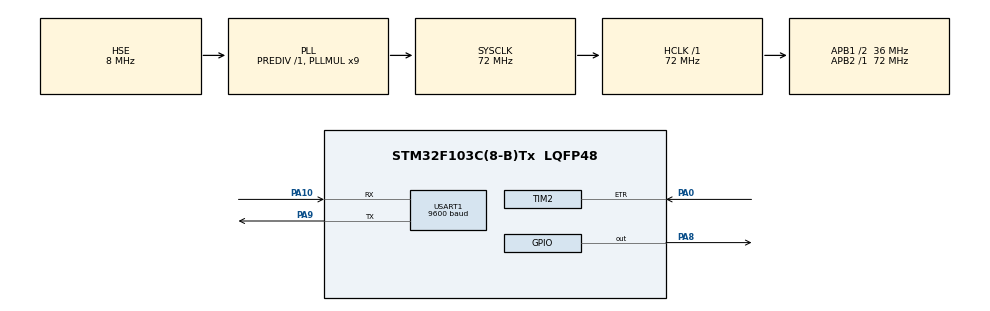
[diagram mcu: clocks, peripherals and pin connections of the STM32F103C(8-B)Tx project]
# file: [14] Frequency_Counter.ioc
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Mcu.Family=STM32F1
RCC.PLLSourceVirtual=RCC_PLLSOURCE_HSE
PD1-OSC_OUT.Mode=HSE-External-Oscillator
PA10.Mode=Asynchronous
TIM3.AutoReloadPreload=TIM_AUTORELOAD_PRELOAD_ENABLE
USART1.BaudRate=9600
PD0-OSC_IN.Signal=RCC_OSC_IN
RCC.APB1CLKDivider=RCC_HCLK_DIV2
VP_SYS_VS_ND.Mode=No_Debug
RCC.SYSCLKSource=RCC_SYSCLKSOURCE_PLLCLK
ProjectManager.StackSize=0x400
PA0-WKUP.Signal=S_TIM2_CH1_ETR
PD1-OSC_OUT.Signal=RCC_OSC_OUT
PA9.Mode=Asynchronous
ProjectManager.TargetToolchain=STM32CubeIDE
RCC.HCLKFreq_Value=72000000
RCC.APB2TimFreq_Value=72000000
PA9.Signal=USART1_TX
RCC.USBFreq_Value=72000000
RCC.AHBFreq_Value=72000000
PD0-OSC_IN.Mode=HSE-External-Oscillator
board=custom
RCC.PLLMUL=RCC_PLL_MUL9
NVIC.TIM3_IRQn=true\:0\:0\:false\:false\:true\:true\:true
RCC.APB2Freq_Value=72000000
TIM3.Prescaler=100
PA8.Signal=GPIO_Output
Mcu.Name=STM32F103C(8-B)Tx
RCC.SYSCLKFreq_VALUE=72000000
Mcu.Package=LQFP48
USART1.VirtualMode=VM_ASYNC
SH.S_TIM2_CH1_ETR.0=TIM2_ETR,ClockSourceETR_Mode2
PA10.Signal=USART1_RX
ProjectManager.HeapSize=0x200
NVIC.PriorityGroup=NVIC_PRIORITYGROUP_4
RCC.APB1TimFreq_Value=72000000
TIM2.AutoReloadPreload=TIM_AUTORELOAD_PRELOAD_ENABLE
RCC.APB1Freq_Value=36000000
VP_TIM3_VS_ClockSourceINT.Mode=Internal

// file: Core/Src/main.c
/* USER CODE BEGIN Header */
/**
  ******************************************************************************
  * @file           : main.c
  * @brief          : Main program body
  ******************************************************************************
  * @attention
  *
  * <h2><center>&copy; Copyright (c) 2020 STMicroelectronics.
  * All rights reserved.</center></h2>
  *
  * This software component is licensed by ST under BSD 3-Clause license,
  * the "License"; You may not use this file except in compliance with the
  * License. You may obtain a copy of the License at:
  *                        opensource.org/licenses/BSD-3-Clause
  *
  ******************************************************************************
  */
/* USER CODE END Header */
#include "main.h"

TIM_HandleTypeDef htim2;
TIM_HandleTypeDef htim3;

UART_HandleTypeDef huart1;

void SystemClock_Config(void);
static void MX_GPIO_Init(void);
static void MX_TIM2_Init(void);
static void MX_TIM3_Init(void);
static void MX_USART1_UART_Init(void);

/* USER CODE BEGIN 0 */

uint32_t gu32_CounterTicks = 0x00;
uint32_t gu32_Freq = 0x00;
uint8_t gu8_MSG[40] ={'\0'};

void HAL_TIM_PeriodElapsedCallback(TIM_HandleTypeDef* htim)
{
	if(htim->Instance == TIM3)
	{
		gu32_CounterTicks = TIM2->CNT;
		gu32_Freq = gu32_CounterTicks * 20;
		sprintf(gu8_MSG, "Frquency = %d Hz\n\r", gu32_Freq);
		HAL_UART_Transmit(&huart1, gu8_MSG, sizeof(gu8_MSG), 100);
		TIM3->CNT = 0;
		TIM2->CNT = 0;
	}

}

/* USER CODE END 0 */

int main(void)
{

  /* MCU Configuration--------------------------------------------------------*/

  /* Reset of all peripherals, Initializes the Flash interface and the Systick. */
  HAL_Init();

  /* Configure the system clock */
  SystemClock_Config();

  /* Initialize all configured peripherals */
  MX_GPIO_Init();
  MX_TIM2_Init();
  MX_TIM3_Init();
  MX_USART1_UART_Init();

  /* Infinite loop */
  while (1)
  {

  }
}

void SystemClock_Config(void)
{
  RCC_OscInitTypeDef RCC_OscInitStruct = {0};
  RCC_ClkInitTypeDef RCC_ClkInitStruct = {0};

  /** Initializes the RCC Oscillators according to the specified parameters
  * in the RCC_OscInitTypeDef structure.
  */
  RCC_OscInitStruct.OscillatorType = RCC_OSCILLATORTYPE_HSE;
  RCC_OscInitStruct.HSEState = RCC_HSE_ON;
  RCC_OscInitStruct.HSEPredivValue = RCC_HSE_PREDIV_DIV1;
  RCC_OscInitStruct.HSIState = RCC_HSI_ON;
  RCC_OscInitStruct.PLL.PLLState = RCC_PLL_ON;
  RCC_OscInitStruct.PLL.PLLSource = RCC_PLLSOURCE_HSE;
  RCC_OscInitStruct.PLL.PLLMUL = RCC_PLL_MUL9;
  if (HAL_RCC_OscConfig(&RCC_OscInitStruct) != HAL_OK)
  {
    Error_Handler();
  }
  /** Initializes the CPU, AHB and APB buses clocks
  */
  RCC_ClkInitStruct.ClockType = RCC_CLOCKTYPE_HCLK|RCC_CLOCKTYPE_SYSCLK
                              |RCC_CLOCKTYPE_PCLK1|RCC_CLOCKTYPE_PCLK2;
  RCC_ClkInitStruct.SYSCLKSource = RCC_SYSCLKSOURCE_PLLCLK;
  RCC_ClkInitStruct.AHBCLKDivider = RCC_SYSCLK_DIV1;
  RCC_ClkInitStruct.APB1CLKDivider = RCC_HCLK_DIV2;
  RCC_ClkInitStruct.APB2CLKDivider = RCC_HCLK_DIV1;

  if (HAL_RCC_ClockConfig(&RCC_ClkInitStruct, FLASH_LATENCY_2) != HAL_OK)
  {
    Error_Handler();
  }
}

static void MX_TIM2_Init(void)
{

  TIM_ClockConfigTypeDef sClockSourceConfig = {0};
  TIM_MasterConfigTypeDef sMasterConfig = {0};

  htim2.Instance = TIM2;
  htim2.Init.Prescaler = 0;
  htim2.Init.CounterMode = TIM_COUNTERMODE_UP;
  htim2.Init.Period = 65535;
  htim2.Init.ClockDivision = TIM_CLOCKDIVISION_DIV1;
  htim2.Init.AutoReloadPreload = TIM_AUTORELOAD_PRELOAD_ENABLE;
  if (HAL_TIM_Base_Init(&htim2) != HAL_OK)
  {
    Error_Handler();
  }
  sClockSourceConfig.ClockSource = TIM_CLOCKSOURCE_ETRMODE2;
  sClockSourceConfig.ClockPolarity = TIM_CLOCKPOLARITY_NONINVERTED;
  sClockSourceConfig.ClockPrescaler = TIM_CLOCKPRESCALER_DIV1;
  sClockSourceConfig.ClockFilter = 0;
  if (HAL_TIM_ConfigClockSource(&htim2, &sClockSourceConfig) != HAL_OK)
  {
    Error_Handler();
  }
  sMasterConfig.MasterOutputTrigger = TIM_TRGO_RESET;
  sMasterConfig.MasterSlaveMode = TIM_MASTERSLAVEMODE_DISABLE;
  if (HAL_TIMEx_MasterConfigSynchronization(&htim2, &sMasterConfig) != HAL_OK)
  {
    Error_Handler();
  }

}

static void MX_TIM3_Init(void)
{

  TIM_ClockConfigTypeDef sClockSourceConfig = {0};
  TIM_MasterConfigTypeDef sMasterConfig = {0};

  htim3.Instance = TIM3;
  htim3.Init.Prescaler = 100;
  htim3.Init.CounterMode = TIM_COUNTERMODE_UP;
  htim3.Init.Period = 65535;
  htim3.Init.ClockDivision = TIM_CLOCKDIVISION_DIV1;
  htim3.Init.AutoReloadPreload = TIM_AUTORELOAD_PRELOAD_ENABLE;
  if (HAL_TIM_Base_Init(&htim3) != HAL_OK)
  {
    Error_Handler();
  }
  sClockSourceConfig.ClockSource = TIM_CLOCKSOURCE_INTERNAL;
  if (HAL_TIM_ConfigClockSource(&htim3, &sClockSourceConfig) != HAL_OK)
  {
    Error_Handler();
  }
  sMasterConfig.MasterOutputTrigger = TIM_TRGO_RESET;
  sMasterConfig.MasterSlaveMode = TIM_MASTERSLAVEMODE_DISABLE;
  if (HAL_TIMEx_MasterConfigSynchronization(&htim3, &sMasterConfig) != HAL_OK)
  {
    Error_Handler();
  }

}

static void MX_USART1_UART_Init(void)
{

  huart1.Instance = USART1;
  huart1.Init.BaudRate = 9600;
  huart1.Init.WordLength = UART_WORDLENGTH_8B;
  huart1.Init.StopBits = UART_STOPBITS_1;
  huart1.Init.Parity = UART_PARITY_NONE;
  huart1.Init.Mode = UART_MODE_TX_RX;
  huart1.Init.HwFlowCtl = UART_HWCONTROL_NONE;
  huart1.Init.OverSampling = UART_OVERSAMPLING_16;
  if (HAL_UART_Init(&huart1) != HAL_OK)
  {
    Error_Handler();
  }

}

static void MX_GPIO_Init(void)
{
  GPIO_InitTypeDef GPIO_InitStruct = {0};

  /* GPIO Ports Clock Enable */
  __HAL_RCC_GPIOD_CLK_ENABLE();
  __HAL_RCC_GPIOA_CLK_ENABLE();

  /*Configure GPIO pin Output Level */
  HAL_GPIO_WritePin(GPIOA, GPIO_PIN_8, GPIO_PIN_RESET);

  /*Configure GPIO pin : PA8 */
  GPIO_InitStruct.Pin = GPIO_PIN_8;
  GPIO_InitStruct.Mode = GPIO_MODE_OUTPUT_PP;
  GPIO_InitStruct.Pull = GPIO_NOPULL;
  GPIO_InitStruct.Speed = GPIO_SPEED_FREQ_LOW;
  HAL_GPIO_Init(GPIOA, &GPIO_InitStruct);

}

void Error_Handler(void)
{
}

/************************ (C) COPYRIGHT STMicroelectronics *****END OF FILE****/
